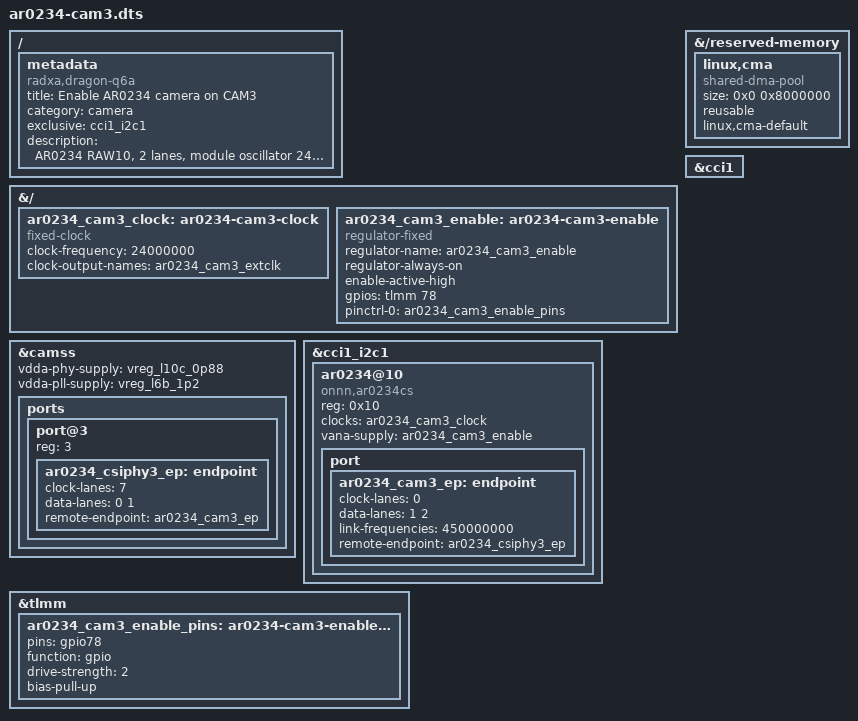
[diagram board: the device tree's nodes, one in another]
// SPDX-License-Identifier: GPL-2.0-only
// Copyright (c) 2025 Radxa Computer (Shenzhen) Co., Ltd.
// Adapted for AR0234 on Q6A CAM3, 2026-10-11.
// CAM3 routing follows Radxa's Q6A IMX219 overlay (BSD-3-Clause).
// This initial configuration assumes the module has a 24 MHz oscillator
// and local sensor voltage regulators. It does not drive an SoC MCLK pin.
/dts-v1/;
/plugin/;

/ {
    metadata {
        title = "Enable AR0234 camera on CAM3";
        compatible = "radxa,dragon-q6a";
        category = "camera";
        exclusive = "cci1_i2c1";
        description = "AR0234 RAW10, 2 lanes, module oscillator 24 MHz.";
    };
};

&{/} {
    ar0234_cam3_clock: ar0234-cam3-clock {
        compatible = "fixed-clock";
        #clock-cells = <0>;
        clock-frequency = <24000000>;
        clock-output-names = "ar0234_cam3_extclk";
    };

    ar0234_cam3_enable: ar0234-cam3-enable {
        compatible = "regulator-fixed";
        regulator-name = "ar0234_cam3_enable";
        regulator-always-on;
        enable-active-high;
        gpios = <&tlmm 78 0>;
        pinctrl-names = "default";
        pinctrl-0 = <&ar0234_cam3_enable_pins>;
    };
};

&{/reserved-memory} {
    linux,cma {
        compatible = "shared-dma-pool";
        size = <0x0 0x8000000>;
        reusable;
        linux,cma-default;
    };
};

&camss {
    vdda-phy-supply = <&vreg_l10c_0p88>;
    vdda-pll-supply = <&vreg_l6b_1p2>;
    status = "okay";
    ports {
        #address-cells = <1>;
        #size-cells = <0>;
        port@3 {
            reg = <3>;
            ar0234_csiphy3_ep: endpoint {
                clock-lanes = <7>;
                data-lanes = <0 1>;
                remote-endpoint = <&ar0234_cam3_ep>;
            };
        };
    };
};

&cci1 { status = "okay"; };

&cci1_i2c1 {
    #address-cells = <1>;
    #size-cells = <0>;
    status = "okay";
    ar0234@10 {
        compatible = "onnn,ar0234cs";
        reg = <0x10>;
        clocks = <&ar0234_cam3_clock>;
        clock-names = "extclk";
        vana-supply = <&ar0234_cam3_enable>;
        port {
            ar0234_cam3_ep: endpoint {
                clock-lanes = <0>;
                data-lanes = <1 2>;
                link-frequencies = /bits/ 64 <450000000>;
                remote-endpoint = <&ar0234_csiphy3_ep>;
            };
        };
    };
};

&tlmm {
    ar0234_cam3_enable_pins: ar0234-cam3-enable-state {
        pins = "gpio78";
        function = "gpio";
        drive-strength = <2>;
        bias-pull-up;
    };
};
